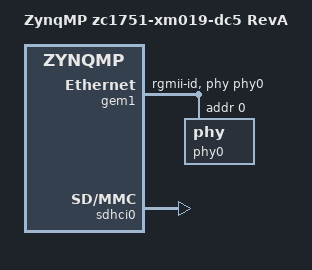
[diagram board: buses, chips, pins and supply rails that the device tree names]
// SPDX-License-Identifier: GPL-2.0+
/*
 * dts file for Xilinx ZynqMP zc1751-xm019-dc5
 *
 * (C) Copyright 2015 - 2018, Xilinx, Inc.
 *
 * Siva Durga Prasad <siva.durga.paladugu@xilinx.com>
 * Michal Simek <michal.simek@xilinx.com>
 */


/ {
	model = "ZynqMP zc1751-xm019-dc5 RevA";
	compatible = "xlnx,zynqmp-zc1751", "xlnx,zynqmp";

	aliases {
		ethernet0 = &gem1;
		i2c0 = &i2c0;
		i2c1 = &i2c1;
		mmc0 = &sdhci0;
		serial0 = &uart0;
		serial1 = &uart1;
	};
};

&gem1 {
	status = "okay";
	phy-handle = <&phy0>;
	phy-mode = "rgmii-id";
	phy0: phy@0 {
		reg = <0>;
	};
};

&sdhci0 {
	status = "okay";
	no-1-8-v;
};
